# STM32N657xx register map
File version: 1.0
Registers are 32-bit, read-write, reset 0x0 unless marked. A register's access mark holds for its fields unless they carry their own. Offsets are from the block's base; [hi:lo] are bit positions; {n}, {i} and the like mark numbered series.

## CSI
Base 0x48006000
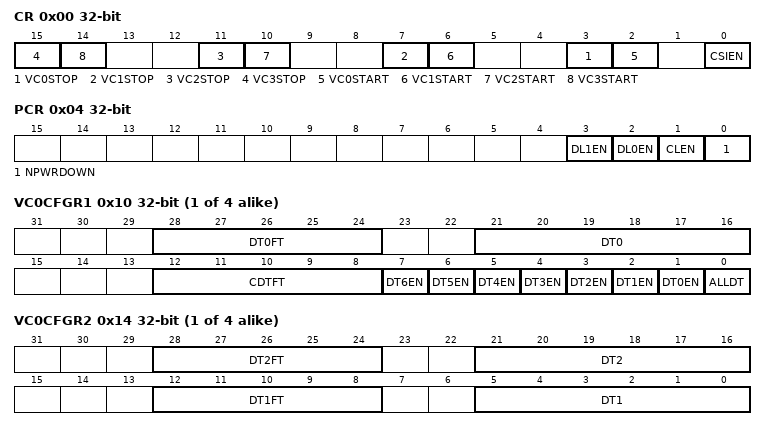
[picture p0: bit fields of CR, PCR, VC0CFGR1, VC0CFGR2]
0x00 CR — CSI-2 Host control register
  [4n+3] VC{n}STOP (n=0..3) — Virtual channel {n} stop
  [4n+2] VC{n}START (n=0..3) — Virtual channel {n} start
  [0] CSIEN — CSI-2 enable
0x04 PCR — CSI-2 Host DPHY_RX control register
  [3] DL1EN — D-PHY_RX data lane 1 enable
  [2] DL0EN — D-PHY_RX data lane 0 enable
  [1] CLEN — Clock lane enable
  [0] NPWRDOWN — Virtual channel 3 start
{0x10+0x10*i} VC{i}CFGR1 (i=0..3) — CSI-2 Host virtual channel {i} configuration register 1
  [28:24] DT0FT — Data type 0 format
  [21:16] DT0 — Data type 0 class selection for virtual channel x
  [12:8] CDTFT — Common format for all data types
  [n+1] DT{n}EN (n=0..6) — Data type {n} enable
  [0] ALLDT — All data types enable for the virtual channel x
{0x14+0x10*i} VC{i}CFGR2 (i=0..3) — CSI-2 Host virtual channel {i} configuration register 2
  [28:24] DT2FT — Data type 2 format
  [21:16] DT2 — Data type 2 class selection for virtual channel x
  [12:8] DT1FT — Data type 1 format
  [5:0] DT1 — Data type 1 class selection for virtual channel x
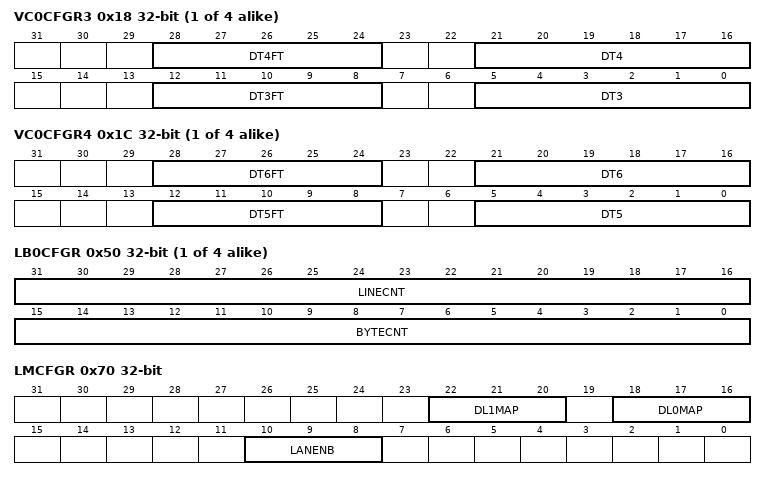
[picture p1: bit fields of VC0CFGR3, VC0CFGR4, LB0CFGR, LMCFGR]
{0x18+0x10*i} VC{i}CFGR3 (i=0..3) — CSI-2 Host virtual channel {i} configuration register 3
  [28:24] DT4FT — Data type 4 format
  [21:16] DT4 — Data type 4 class selection for virtual channel x
  [12:8] DT3FT — Data type 3 format
  [5:0] DT3 — Data type 3 class selection for virtual channel x
{0x1C+0x10*i} VC{i}CFGR4 (i=0..3) — CSI-2 Host virtual channel {i} configuration register 4
  [28:24] DT6FT — Data type 6 format
  [21:16] DT6 — Data type 6 class selection for virtual channel x
  [12:8] DT5FT — Data type 5 format
  [5:0] DT5 — Data type 5 class selection for virtual channel x
{0x50+4i} LB{i}CFGR (i=0..3) — CSI-2 Host line byte {i} configuration register
  [31:16] LINECNT — Line counter
  [15:0] BYTECNT — Byte counter
{0x60+4i} TIM{i}CFGR (i=0..3) — CSI-2 Host timer {i} configuration register
  [24:0] COUNT — Clock cycle counter
0x70 LMCFGR — CSI-2 Host lane merger configuration register
  [22:20] DL1MAP — Physical mapping of logical data lane 1
  [18:16] DL0MAP — Physical mapping of logical data lane 0
  [10:8] LANENB — Number of lanes
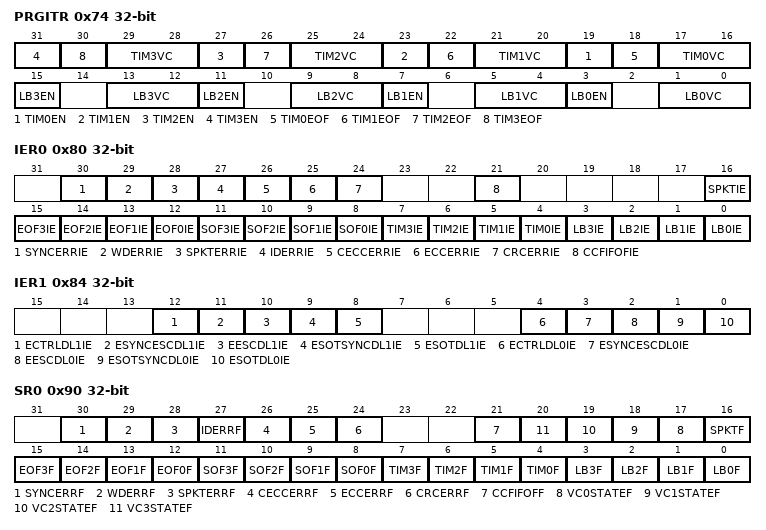
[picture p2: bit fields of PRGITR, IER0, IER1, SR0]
0x74 PRGITR — CSI-2 Host program interrupt register
  [4n+19] TIM{n}EN (n=0..3) — TIM{n} base time enable
  [4n+18] TIM{n}EOF (n=0..3) — TIM{n} base time starting from the end of frame
  [4n+17:4n+16] TIM{n}VC (n=0..3) — TIM{n} base time linked to a virtual channel
  [15] LB3EN — Line/Byte 3 counter enable
  [4n+1:4n] LB{n}VC (n=0..3) — Line/Byte counter {n} linked to a virtual channel
  [11] LB2EN — Line/Byte 2 counter enable
  [7] LB1EN — Line/Byte 1 counter enable
  [3] LB0EN — Line/Byte 0counter enable
0x78 WDR — CSI-2 Host watchdog register
  [31:0] CNT — Watchdog counter
0x80 IER0 — CSI-2 Host Interrupt enable register 0
  [30] SYNCERRIE — Invalid synchronization error interrupt enable
  [29] WDERRIE — Watchdog error interrupt enable
  [28] SPKTERRIE — Short packet error interrupt enable
  [27] IDERRIE — Data type ID error interrupt enable
  [26] CECCERRIE — Corrected ECC error interrupt enable
  [25] ECCERRIE — ECC error interrupt enable
  [24] CRCERRIE — CRC error interrupt enable
  [21] CCFIFOFIE — Clock changer FIFO full interrupt enable
  [16] SPKTIE — Short packet interrupt enable
  [n+12] EOF{n}IE (n=0..3) — End of frame for virtual channel {n} interrupt enable
  [n+8] SOF{n}IE (n=0..3) — Start of frame for virtual channel {n} interrupt enable
  [n+4] TIM{n}IE (n=0..3) — Timer {n} interrupt enable
  [n] LB{n}IE (n=0..3) — Line byte counter {n} interrupt enable
0x84 IER1 — CSI-2 Host Interrupt enable register 1
  [12] ECTRLDL1IE — D-PHY_RX lane 1 control error interrupt enable
  [11] ESYNCESCDL1IE — D-PHY_RX lane 1 low power data transmission synchronization error interrupt enable
  [10] EESCDL1IE — D-PHY_RX lane 1 escape entry error interrupt enable
  [9] ESOTSYNCDL1IE — Start of transmission synchronization interrupt error enable on lane 1
  [8] ESOTDL1IE — Start of transmission error interrupt enable on lane 1
  [4] ECTRLDL0IE — D-PHY_RX lane 0 control error interrupt enable
  [3] ESYNCESCDL0IE — D-PHY_RX lane 0 low power data transmission synchronization error interrupt enable
  [2] EESCDL0IE — D-PHY_RX lane 0 escape entry error interrupt enable
  [1] ESOTSYNCDL0IE — Start of transmission synchronization interrupt error enable on lane 0
  [0] ESOTDL0IE — Start of transmission error interrupt enable on lane 0
0x90 SR0 — CSI-2 Host status register 0
  [30] SYNCERRF — Invalid synchronization error flag
  [29] WDERRF — Watchdog error flag
  [28] SPKTERRF — Short packet error flag
  [27] IDERRF — Data type ID error flag
  [26] CECCERRF — Corrected ECC error flag
  [25] ECCERRF — ECC error flag
  [24] CRCERRF — CRC error flag
  [21] CCFIFOFF — Clock changer FIFO full flag
  [n+17] VC{n}STATEF (n=0..3) — Virtual channel {n} state flag
  [16] SPKTF — Short packet flag
  [n+12] EOF{n}F (n=0..3) — End of frame flag for virtual channel {n}
  [n+8] SOF{n}F (n=0..3) — Start of frame flag for virtual channel {n}
  [n+4] TIM{n}F (n=0..3) — Timer {n} flag
  [n] LB{n}F (n=0..3) — Line byte counter {n} flag
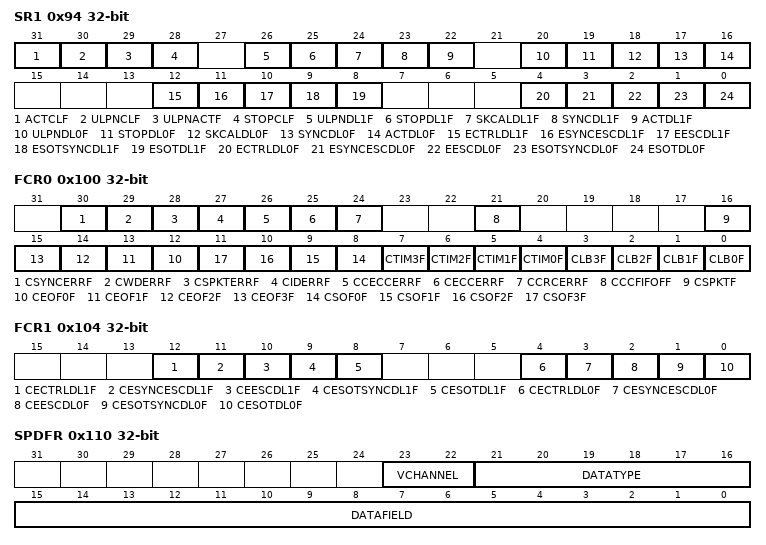
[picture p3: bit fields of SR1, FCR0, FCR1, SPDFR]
0x94 SR1 — CSI-2 Host status register 1
  [31] ACTCLF — D-PHY_RX receiver clock active flag
  [30] ULPNCLF — D-PHY_RX receiver Ultra-Low power state (not) on clock lane
  [29] ULPNACTF — D-PHY_RX receiver ULP state (not) active
  [28] STOPCLF — D-PHY_RX receiver in stop state for the clock lane
  [26] ULPNDL1F — D-PHY_RX receiver Ultra low power state (not) Active on data lane 1
  [25] STOPDL1F — D-PHY_RX receiver data lane 1 in stop state
  [24] SKCALDL1F — D-PHY_RX lane 1 High speed skew calibration
  [23] SYNCDL1F — D-PHY_RX lane 1 receiver synchronization observed
  [22] ACTDL1F — D-PHY_RX lane 1 High speed reception active
  [20] ULPNDL0F — D-PHY_RX receiver Ultra low power state (not) Active on data lane 00
  [19] STOPDL0F — D-PHY_RX receiver data lane 0 in stop state
  [18] SKCALDL0F — D-PHY_RX lane 0 High speed skew calibration
  [17] SYNCDL0F — D-PHY_RX lane 0 receiver synchronization observed
  [16] ACTDL0F — D-PHY_RX lane 0 High speed reception active
  [12] ECTRLDL1F — D-PHY_RX lane 1 control error flag
  [11] ESYNCESCDL1F — D-PHY_RX lane 1 low power data transmission synchronization error flag
  [10] EESCDL1F — D-PHY_RX lane 1 escape entry error flag
  [9] ESOTSYNCDL1F — Start of transmission synchronization error flag on lane 1
  [8] ESOTDL1F — Start of transmission error flag on lane 1
  [4] ECTRLDL0F — D-PHY_RX lane 0 control error flag
  [3] ESYNCESCDL0F — D-PHY_RX lane 0 low power data transmission synchronization error flag
  [2] EESCDL0F — D-PHY_RX lane 0 escape entry error flag
  [1] ESOTSYNCDL0F — Start of transmission synchronization error flag on lane 0
  [0] ESOTDL0F — Start of transmission error flag on lane 0
0x100 FCR0 — CSI-2 Host Flag clear register 0
  [30] CSYNCERRF — Clear Invalid synchronization error flag
  [29] CWDERRF — Clear Watchdog error flag
  [28] CSPKTERRF — Clear Short packet error flag
  [27] CIDERRF — Clear Data type ID error flag
  [26] CCECCERRF — Clear Corrected ECC error flag
  [25] CECCERRF — Clear ECC error flag
  [24] CCRCERRF — Clear CRC error flag
  [21] CCCFIFOFF — Clear Clock changer FIFO full flag
  [16] CSPKTF — Clear Short packet flag
  [n+12] CEOF{n}F (n=0..3) — Clear End of frame flag for virtual channel {n}
  [n+8] CSOF{n}F (n=0..3) — Clear Start of frame flag for virtual channel {n}
  [n+4] CTIM{n}F (n=0..3) — Clear Timer {n} flag
  [n] CLB{n}F (n=0..3) — Clear Line byte counter {n} flag
0x104 FCR1 — CSI-2 Host Flag clear register 1
  [12] CECTRLDL1F — Clear D-PHY_RX lane 1 control error flag
  [11] CESYNCESCDL1F — Clear D-PHY_RX lane 1 low power data transmission synchronization error flag
  [10] CEESCDL1F — Clear D-PHY_RX lane 1 escape entry error flag
  [9] CESOTSYNCDL1F — Clear Start of transmission synchronization error flag on lane 1
  [8] CESOTDL1F — Clear Start of transmission error flag on lane 1
  [4] CECTRLDL0F — Clear D-PHY_RX lane 0 control error flag
  [3] CESYNCESCDL0F — Clear D-PHY_RX lane 0 low power data transmission synchronization error flag
  [2] CEESCDL0F — Clear D-PHY_RX lane 0 escape entry error flag
  [1] CESOTSYNCDL0F — Clear Start of transmission synchronization error flag on lane 0
  [0] CESOTDL0F — Clear Start of transmission error flag on lane 0
0x110 SPDFR — CSI-2 Host short packet data field register
  [23:22] VCHANNEL — Virtual channel
  [21:16] DATATYPE — Data type class
  [15:0] DATAFIELD
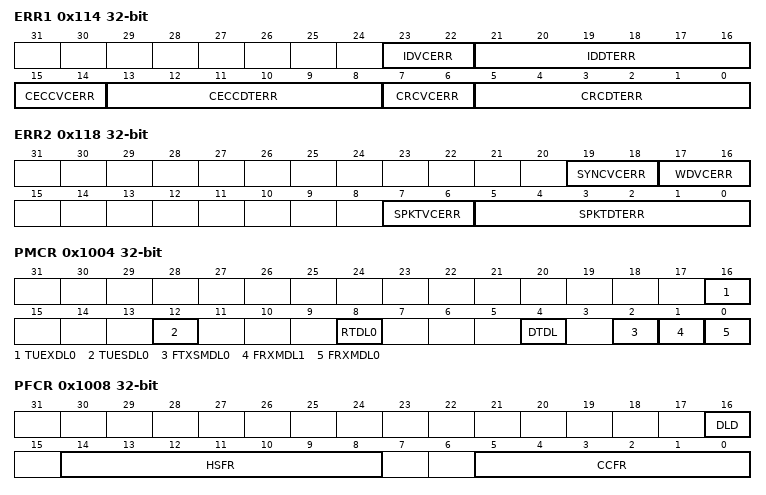
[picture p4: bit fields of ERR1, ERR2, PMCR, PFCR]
0x114 ERR1 — CSI-2 Host error register 1
  [23:22] IDVCERR — Virtual channel having ID error
  [21:16] IDDTERR — Data type in error
  [15:14] CECCVCERR — Virtual channel having a corrected ECC error
  [13:8] CECCDTERR — Data type having a corrected ECC error
  [7:6] CRCVCERR — Virtual channel having a CRC error
  [5:0] CRCDTERR — Data type having a CRC error
0x118 ERR2 — CSI-2 Host error register 2
  [19:18] SYNCVCERR — Virtual channel having synchronization error
  [17:16] WDVCERR — Virtual channel having a watchdog error
  [7:6] SPKTVCERR — Virtual channel having a short packet error
  [5:0] SPKTDTERR — Data type having a short packet error
0x1000 PRCR — CSI PHY reset control register
  [1] PEN — When set to 0, this bit places the digital section of the D-PHY in the reset state
0x1004 PMCR — CSI PHY mode control register
  [16] TUEXDL0 — Tx ULP Exit-sequence Data Lane 0
  [12] TUESDL0 — Tx ULP Escape-mode Data Lane 0
  [8] RTDL0 — Turn-around Request Data Lane 0
  [4] DTDL — Disable Turn-around Data Lane 0
  [2] FTXSMDL0 — Force to Tx Stop Mode the Data Lane 0
  [1] FRXMDL1 — Force to Rx Mode the Data Lane 1
  [0] FRXMDL0 — Force to Rx Mode the Data Lane 0
0x1008 PFCR — CSI PHY frequency control register
  [16] DLD — Data Lane Direction of lane0
  [14:8] HSFR — PHY-high-speed Frequency Range selection
  [5:0] CCFR — Configuration Clock Frequency Range selection
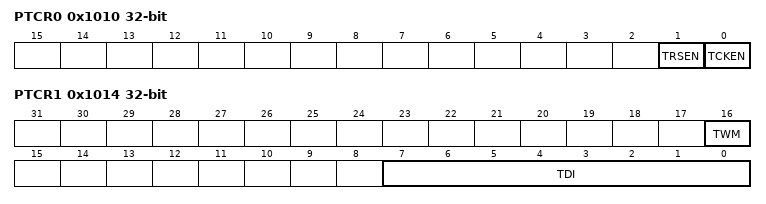
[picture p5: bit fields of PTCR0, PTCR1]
0x1010 PTCR0 — CSI PHY test control register 0
  [1] TRSEN — Test-interface Reset Enable for the TDI bus into the PHY
  [0] TCKEN — Test-interface Clock Enable for the TDI bus into the PHY
0x1014 PTCR1 — CSI PHY test control register 1
  [16] TWM — Test-interface Write Mode selector
  [7:0] TDI — Test-interface Data In
0x1018 PTSR — CSI PHY test status register
  [7:0] TDO — CSI PHY test interface data output bus for read-back and internal probing functionalities
